# PIC32MK0128MCA048 device description
Architecture: MIPS; Family: PIC32MK; Series: PIC32MK
Registers are 32-bit, read-write, no defined reset value unless marked. A register's access mark holds for its fields unless they carry their own. Offsets are from the block's base; [hi:lo] are bit positions; {n}, {i} and the like mark numbered series.

## CDAC
Instances: CDAC 0x1f82c600 in periph_pb2_std
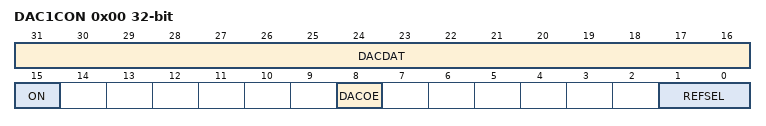
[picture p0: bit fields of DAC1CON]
0x00 DAC1CON — CDAC Control Register
  [31:16] DACDAT — Data Input Register Bits for the CDAC
  [15] ON — CDAC Enable
    0=The CDAC is Disabled; 1=The CDAC is Enabled
  [8] DACOE — CDAC Output Enable
    0=Output is Disabled; drive to pin is floating; 1=Output is Enabled; CDAC voltage is connected to the pin
  [1:0] REFSEL — Reference Source Select
    0=No reference is selected (output is AVSS); 3=Reference voltage is AVDD

## CFG
Instances: CFG 0x1f800000 in periph_pb1_std
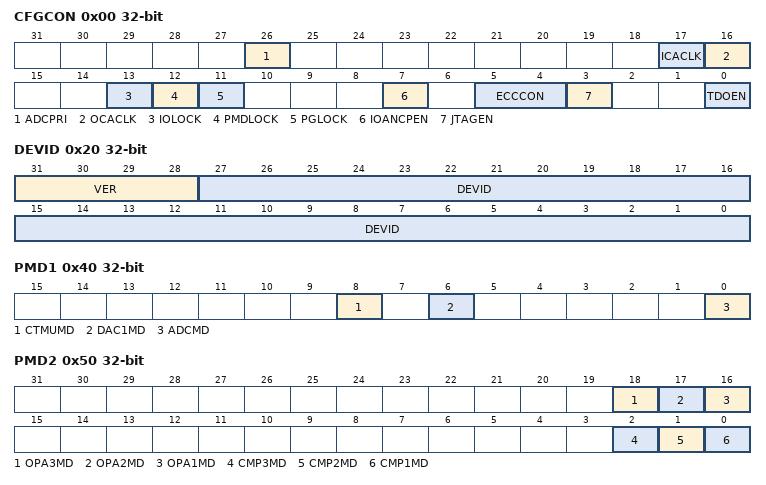
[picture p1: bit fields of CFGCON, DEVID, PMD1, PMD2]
0x00 CFGCON — Configuration Control Register
  [26] ADCPRI — ADC Arbitration Priority to SRAM bit
    1=ADC gets High Priority access to SRAM; 0=ADC uses Least Recently Serviced Arbitration (same as other initiators)
  [17] ICACLK — Input Capture Alternate Clock Selection bit
    1=Input Capture modules use an alternative Timer pair as their timebase clock; 0=All Input Capture modules use Timer2/3 as their timebase clock
  [16] OCACLK — Output Compare Alternate Clock Selection bit
    1=Output Compare modules use an alternative Timer pair as their timebase clock; 0=All Output Compare modules use Timer2/3 as their timebase clock
  [13] IOLOCK — Peripheral Pin Select Lock bit
    1=Peripheral Pin Select is locked. Writes to PPS registers are not allowed; 0=Peripheral Pin Select is not locked. Writes to PPS registers are allowed
  [12] PMDLOCK — Peripheral Module Disable bit
    1=Peripheral module is locked. Writes to PMD registers are not allowed; 0=Peripheral module is not locked. Writes to PMD registers are allowed
  [11] PGLOCK — Permission Group Lock bit
    1=Permission Group registers are locked. Writes to PG registers are not allowed; 0=Permission Group registers are not locked. Writes to PG registers are allowed
  [7] IOANCPEN — I/O Analog Charge Pump Enable bit
    1=Charge pump is enabled; 0=Charge pump is disabled (default)
  [5:4] ECCCON — Flash ECC Configuration bits
    3=ECC and dynamic ECC are disabled (ECCCON bits are writable); 2=ECC and dynamic ECC are disabled (ECCCON bits are locked); 1=Dynamic Flash ECC is enabled (ECCCON bits are locked); 0=Flash ECC is enabled (ECCCON bits are locked; disables word Flash writes)
  [3] JTAGEN — JTAG Port Enable bit
    1=Enable the JTAG port; 0=Disable the JTAG port
  [0] TDOEN — TDO Enable for 2-Wire JTAG
    1=2-wire JTAG protocol uses TDO; 0=2-wire JTAG protocol does not use TDO
0x20 DEVID
  [31:28] VER, [27:0] DEVID
0x30 SYSKEY
0x40 PMD1
  [8] CTMUMD, [6] DAC1MD, [0] ADCMD
0x50 PMD2
  [18] OPA3MD, [17] OPA2MD, [16] OPA1MD, [2] CMP3MD, [1] CMP2MD, [0] CMP1MD
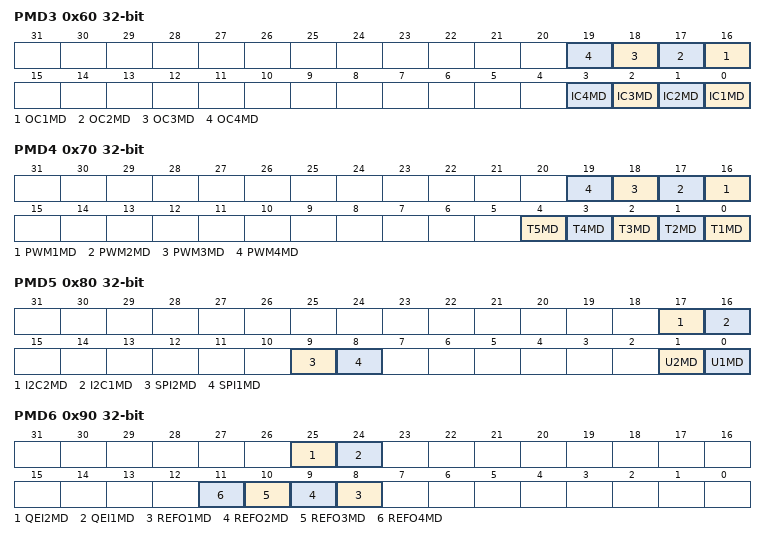
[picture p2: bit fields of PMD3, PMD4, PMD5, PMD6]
0x60 PMD3
  [n+15] OC{n}MD (n=1..4), [n-1] IC{n}MD (n=1..4)
0x70 PMD4
  [n+15] PWM{n}MD (n=1..4), [n-1] T{n}MD (n=1..5)
0x80 PMD5
  [17] I2C2MD, [16] I2C1MD, [9] SPI2MD, [8] SPI1MD, [1] U2MD, [0] U1MD
0x90 PMD6
  [25] QEI2MD, [24] QEI1MD, [n+7] REFO{n}MD (n=1..4)
0xA0 PMD7
  [4] DMAMD
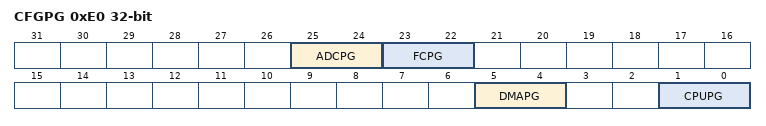
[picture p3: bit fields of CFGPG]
0xE0 CFGPG — Permission Group Configuration Register
  [all] fields
    {v}=(If RDPER({v}) is 1) read access / (If WRPER({v}) is 1) write access (v=0..3)
  [25:24] ADCPG — ADC Permission bits
  [23:22] FCPG — Flash Control Permission Group bits
  [5:4] DMAPG — DMA Module Permission Group bits
  [1:0] CPUPG — CPU Instruction Space Permission Group bits

## CLC
Instances: CLC 0x1f82d200 in periph_pb2_std
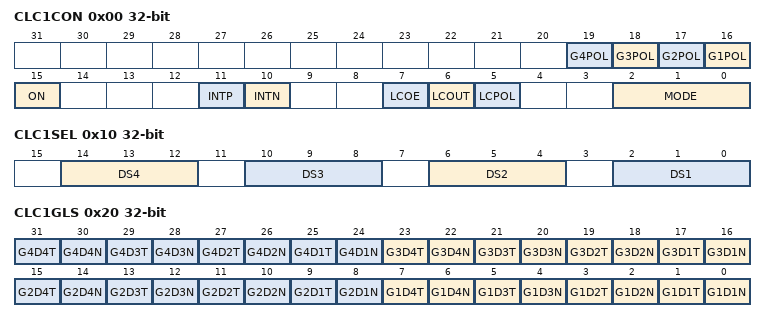
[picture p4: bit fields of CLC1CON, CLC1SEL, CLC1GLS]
0x00 CLC1CON
  [n+15] G{n}POL (n=1..4) — Gate {n} Polarity Control bit
    1=The output of Channel {n} logic is inverted when applied to the logic cell; 0=The output of Channel {n} logic is not inverted
  [15] ON — CLCx Enable bit
    1=CLCx is enabled and mixing input signals; 0=CLCx is disabled and has logic zero outputs
  [11] INTP — CLCx Positive Edge Interrupt Enable bit
    1=Interrupt will be generated when a rising edge occurs on LCOUT; 0=Interrupt will not be generated
  [10] INTN — CLCx Negative Edge Interrupt Enable bit
    1=Interrupt will be generated when a falling edge occurs on LCOUT; 0=Interrupt will not be generated
  [7] LCOE — CLCx Port Enable bit
    1=CLCx port pin output is enabled; 0=CLCx port pin output is disabled
  [6] LCOUT — CLCx Data Output Status bit
    1=CLCx output high; 0=CLCx output low
  [5] LCPOL — CLCx Output Polarity Control bit
    1=The output of the module is inverted; 0=The output of the module is not inverted
  [2:0] MODE — CLCx Mode bits
    7=Cell is a 1-input transparent latch with S and R; 6=Cell is a JK flip-flop with R; 5=Cell is a 2-input D flip-flop with R; 4=Cell is a 1-input D flip-flop with S and R; 3=Cell is an SR latch; 2=Cell is a 4-input AND; 1=Cell is an OR-XOR; 0=Cell is a AND-OR
0x10 CLC1SEL
  [14:12] DS4 — Data Selection MUX 4 Signal Selection bits
    7=UART1 BCLK/RTS; 6=OCMP4 event; 5=ICAP4 event; 4=RTCC event; 3=SPI1 SDI1 in; 2=TMR2 Sync Out; 1=CLC2 out; 0=CLCINB I/O pin
  [10:8] DS3 — Data Selection MUX 3 Signal Selection bits
    7=TMR4 Compare match event; 6=OCMP3 event; 5=ICAP3 event; 4=UART1 RX In; 3=SPI SDO Out; 2=CMP2 out; 1=CLC1 Out; 0=CLCINA I/O pin
  [6:4] DS2 — Data Selection MUX 2 Signal Selection bits
    7=TMR3 compare match event; 6=OCMP2 event; 5=ICAP2 event; 4=ADC7 End of Conversion; 3=UART1 TX Out; 2=CMP1 out; 1=CLC2 out; 0=CLCINB I/O pin
  [2:0] DS1 — Data Selection MUX 1 Signal Selection bits
    7=TMR2 compare match event; 6=OCMP1 event; 5=ICAP1 event; 4=REFO2 Clock Output; 3=LPRC Clock; 2=SOSC Clock; 1=System Clock; 0=CLCINA I/O pin
0x20 CLC1GLS
  [8n-1] G{n}D4T (n=1..4) — Gate {n} Data Source 4 True Enable bit
    1=The Data Source 4 signal is enabled for Gate {n}; 0=The Data Source 4 signal is disabled for Gate {n}
  [8n-2] G{n}D4N (n=1..4) — Gate {n} Data Source 4 Negated Enable bit
    1=The Data Source 4 inverted signal is enabled for Gate {n}; 0=The Data Source 4 inverted signal is disabled for Gate {n}
  [8n-3] G{n}D3T (n=1..4) — Gate {n} Data Source 3 True Enable bit
    1=The Data Source 3 signal is enabled for Gate {n}; 0=The Data Source 3 signal is disabled for Gate {n}
  [8n-4] G{n}D3N (n=1..4) — Gate {n} Data Source 3 Negated Enable bit
    1=The Data Source 3 inverted signal is enabled for Gate {n}; 0=The Data Source 3 inverted signal is disabled for Gate {n}
  [8n-5] G{n}D2T (n=1..4) — Gate {n} Data Source 2 True Enable bit
    1=The Data Source 2 signal is enabled for Gate {n}; 0=The Data Source 2 signal is disabled for Gate {n}
  [8n-6] G{n}D2N (n=1..4) — Gate {n} Data Source 2 Negated Enable bit
    1=The Data Source 2 inverted signal is enabled for Gate {n}; 0=The Data Source 2 inverted signal is disabled for Gate {n}
  [8n-7] G{n}D1T (n=1..4) — Gate {n} Data Source 1 True Enable bit
    1=The Data Source 1 signal is enabled for Gate {n}; 0=The Data Source 1 signal is disabled for Gate {n}
  [8n-8] G{n}D1N (n=1..4) — Gate {n} Data Source 1 Negated Enable bit
    1=The Data Source 1 inverted signal is enabled for Gate {n}; 0=The Data Source 1 inverted signal is disabled for Gate {n}

## Notices in the file
Copyright (c) 2019 Microchip Technology Inc.
SPDX-License-Identifier: Apache-2.0
Licensed under the Apache License, Version 2.0 (the "License");
you may not use this file except in compliance with the License.
You may obtain a copy of the License at
http://www.apache.org/licenses/LICENSE-2.0
Unless required by applicable law or agreed to in writing, software
distributed under the License is distributed on an "AS IS" BASIS,
WITHOUT WARRANTIES OR CONDITIONS OF ANY KIND, either express or implied.
See the License for the specific language governing permissions and
limitations under the License.
